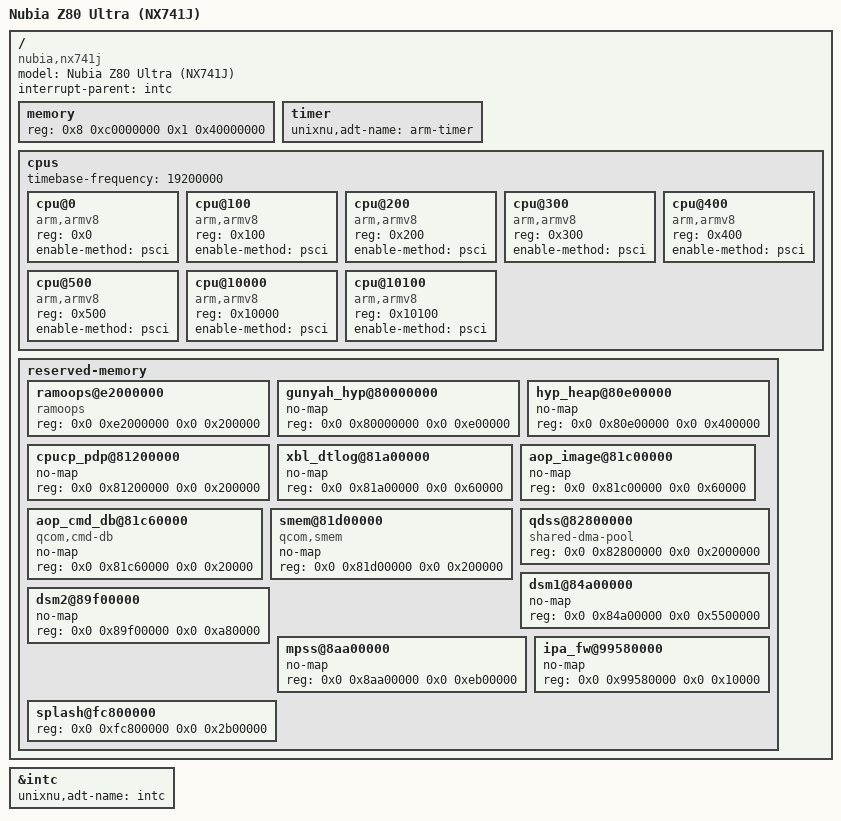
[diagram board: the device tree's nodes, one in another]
/dts-v1/;

/*
 * NX741J 板级设备树（对应 https://unixnu.com/zh/porting/device-tree#procedure）
 *
 * 结构：
 *   - SoC 层：/include/ "sm8850.dtsi"
/include/ "nx741j-hw.dtsi"（来自 feeds.toml 的 sm8850 源，include_dirs = soc:dts）
 *   - 板级层：本文件只放本机差异项（model / compatible / memory / CPU 时基）
 *
 * 说明：此前本文件把 SoC 节点（psci/timer/gic）复制了一份，与 sm8850.dtsi 内容重复；
 *       改为 include 后编译出的 DTB 与原文件一致（1660 字节），但维护时只有一处来源。
 */

/include/ "sm8850.dtsi"

/ {
    model = "Nubia Z80 Ultra (NX741J)";
    compatible = "nubia,nx741j", "qcom,alor", "qcom,sm8850";
    #address-cells = <2>;
    #size-cells = <2>;
    interrupt-parent = <&intc>;

    memory {
        device_type = "memory";
        /*
         * 官方 ADT 生成器要求单一连续 DRAM 范围，这里取实机 DTB 中最大的连续区
         * （0x8C0000000 + 5 GiB）。实机共 21 段、合计 0x3CF4F8000（15.24 GiB），
         * 完整布局见 docs/STEP6-PLATFORM.md，内核启动后按实际映射再调整。
         */
        reg = <0x8 0xc0000000 0x1 0x40000000>;
    };

    timer {
        /* exported as the ARM generic timer node by the shared generator */
        unixnu,adt-name = "arm-timer";
    };

    cpus {
        timebase-frequency = <19200000>;
        #address-cells = <1>;
        #size-cells = <0>;
        cpu@0 { device_type = "cpu"; compatible = "arm,armv8"; reg = <0x0>; enable-method = "psci"; };
        cpu@100 { device_type = "cpu"; compatible = "arm,armv8"; reg = <0x100>; enable-method = "psci"; };
        cpu@200 { device_type = "cpu"; compatible = "arm,armv8"; reg = <0x200>; enable-method = "psci"; };
        cpu@300 { device_type = "cpu"; compatible = "arm,armv8"; reg = <0x300>; enable-method = "psci"; };
        cpu@400 { device_type = "cpu"; compatible = "arm,armv8"; reg = <0x400>; enable-method = "psci"; };
        cpu@500 { device_type = "cpu"; compatible = "arm,armv8"; reg = <0x500>; enable-method = "psci"; };
        cpu@10000 { device_type = "cpu"; compatible = "arm,armv8"; reg = <0x10000>; enable-method = "psci"; };
        cpu@10100 { device_type = "cpu"; compatible = "arm,armv8"; reg = <0x10100>; enable-method = "psci"; };
    };
};

/* The shared ADT generator exports enabled nodes that carry unixnu,adt-name into
 * /arm-io. XNU's platform expert needs the GIC there, otherwise /arm-io has no
 * interrupt controller and stage 5 cannot start. */
&intc {
    unixnu,adt-name = "intc";
};

/* Reserved regions copied from the stock FDT (DTB-PARAMETERS.md). The shared ADT
 * generator exports only nodes with unixnu,adt-name, so these stay in the firmware DTB
 * and document the memory map for the platform/drivers. */
/ {
    reserved-memory {
        #address-cells = <2>;
        #size-cells = <2>;
        ranges;

        ramoops@e2000000      { compatible = "ramoops"; reg = <0x0 0xe2000000 0x0 0x200000>; };
        gunyah_hyp@80000000   { no-map; reg = <0x0 0x80000000 0x0 0xe00000>; };
        hyp_heap@80e00000     { no-map; reg = <0x0 0x80e00000 0x0 0x400000>; };
        cpucp_pdp@81200000    { no-map; reg = <0x0 0x81200000 0x0 0x200000>; };
        xbl_dtlog@81a00000    { no-map; reg = <0x0 0x81a00000 0x0 0x60000>; };
        aop_image@81c00000    { no-map; reg = <0x0 0x81c00000 0x0 0x60000>; };
        aop_cmd_db@81c60000   { compatible = "qcom,cmd-db"; no-map; reg = <0x0 0x81c60000 0x0 0x20000>; };
        smem@81d00000         { compatible = "qcom,smem"; no-map; reg = <0x0 0x81d00000 0x0 0x200000>; };
        qdss@82800000         { compatible = "shared-dma-pool"; reg = <0x0 0x82800000 0x0 0x2000000>; };
        dsm1@84a00000         { no-map; reg = <0x0 0x84a00000 0x0 0x5500000>; };
        dsm2@89f00000         { no-map; reg = <0x0 0x89f00000 0x0 0xa80000>; };
        mpss@8aa00000         { no-map; reg = <0x0 0x8aa00000 0x0 0xeb00000>; };
        ipa_fw@99580000       { no-map; reg = <0x0 0x99580000 0x0 0x10000>; };
        splash@fc800000       { reg = <0x0 0xfc800000 0x0 0x2b00000>; };
    };
};
